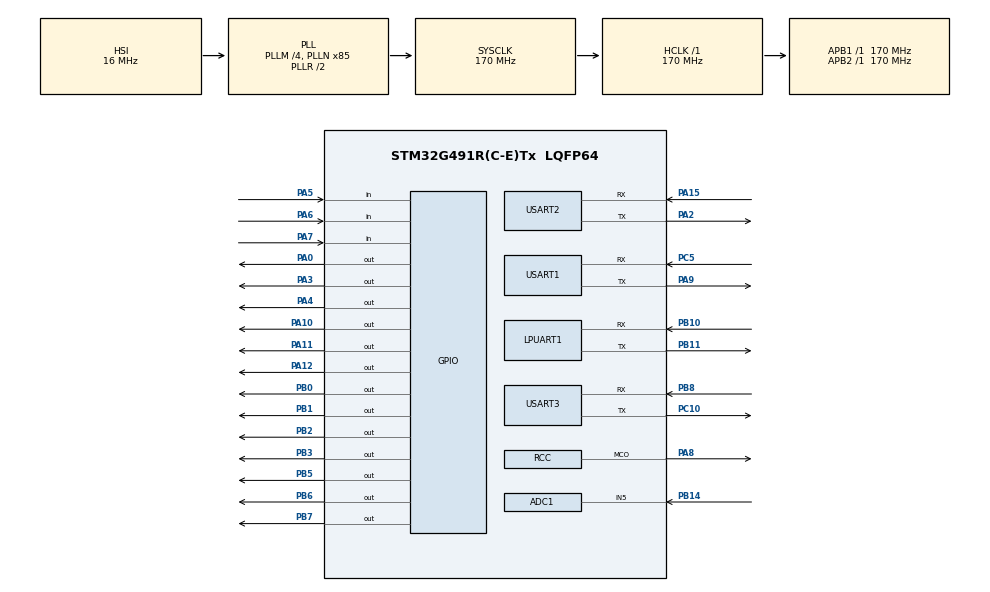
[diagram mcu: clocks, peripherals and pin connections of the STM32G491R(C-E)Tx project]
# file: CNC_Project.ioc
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ADC1.Channel-0\#ChannelRegularConversion=ADC_CHANNEL_5
ADC1.NbrOfConversionFlag=1
ADC1.OffsetNumber-0\#ChannelRegularConversion=ADC_OFFSET_NONE
ADC1.Rank-0\#ChannelRegularConversion=1
ADC1.SamplingTime-0\#ChannelRegularConversion=ADC_SAMPLETIME_2CYCLES_5
ADC1.master=1
Mcu.Family=STM32G4
Mcu.Name=STM32G491R(C-E)Tx
Mcu.Package=LQFP64
NVIC.LPUART1_IRQn=true\:5\:0\:true\:false\:true\:true\:true\:true
NVIC.PriorityGroup=NVIC_PRIORITYGROUP_4
NVIC.RCC_IRQn=true\:0\:0\:false\:false\:true\:true\:false\:true
PA0.Signal=GPIO_Output
PA10.Signal=GPIO_Output
PA11.Signal=GPIO_Output
PA12.Signal=GPIO_Output
PA13.Mode=Serial_Wire
PA13.Signal=SYS_JTMS-SWDIO
PA14.Mode=Serial_Wire
PA14.Signal=SYS_JTCK-SWCLK
PA15.Mode=Asynchronous
PA15.Signal=USART2_RX
PA2.Mode=Asynchronous
PA2.Signal=USART2_TX
PA3.Signal=GPIO_Output
PA4.Signal=GPIO_Output
PA5.Signal=GPIO_Input
PA6.Signal=GPIO_Input
PA7.Signal=GPIO_Input
PA8.Mode=Clock-out
PA8.Signal=RCC_MCO
PA9.Mode=Asynchronous
PA9.Signal=USART1_TX
PB0.Signal=GPIO_Output
PB1.Signal=GPIO_Output
PB10.Mode=Asynchronous
PB10.Signal=LPUART1_RX
PB11.Mode=Asynchronous
PB11.Signal=LPUART1_TX
PB12.Signal=TIM1_BKIN
PB14.Signal=SharedAnalog_PB14
PB2.Signal=GPIO_Output
PB3.Signal=GPIO_Output
PB4.Signal=S_TIM3_CH1
PB5.Signal=GPIO_Output
PB6.Signal=GPIO_Output
PB7.Signal=GPIO_Output
PB8-BOOT0.Mode=Asynchronous
PB8-BOOT0.Signal=USART3_RX
PC0.Signal=S_TIM1_CH1
PC1.Signal=S_TIM1_CH2
PC10.Mode=Asynchronous
PC10.Signal=USART3_TX
PC2.Signal=S_TIM20_CH2
PC5.Mode=Asynchronous
PC5.Signal=USART1_RX
ProjectManager.HeapSize=0x200
ProjectManager.StackSize=0x400
ProjectManager.TargetToolchain=STM32CubeIDE
RCC.ADC12Freq_Value=170000000
RCC.ADC345Freq_Value=170000000
RCC.AHBFreq_Value=170000000
RCC.APB1Freq_Value=170000000
RCC.APB1TimFreq_Value=170000000
RCC.APB2Freq_Value=170000000
RCC.APB2TimFreq_Value=170000000
RCC.CortexFreq_Value=170000000
RCC.EXTERNAL_CLOCK_VALUE=12288000
RCC.HCLKFreq_Value=170000000
RCC.HSE_VALUE=8000000
RCC.HSI48_VALUE=48000000
RCC.HSI_VALUE=16000000
RCC.LSE_VALUE=32768
RCC.PLLM=RCC_PLLM_DIV4
RCC.PLLN=85
RCC.SYSCLKFreq_VALUE=170000000
RCC.SYSCLKSource=RCC_SYSCLKSOURCE_PLLCLK
RCC.VCOOutputFreq_Value=340000000
SH.S_TIM1_CH1.0=TIM1_CH1
SH.S_TIM1_CH2.0=TIM1_CH2
SH.S_TIM20_CH2.0=TIM20_CH2
SH.S_TIM3_CH1.0=TIM3_CH1
SH.SharedAnalog_PB14.0=GPIO_Analog
SH.SharedAnalog_PB14.1=ADC1_IN5,IN5-Single-Ended
USART1.VirtualMode-Asynchronous=VM_ASYNC
USART2.VirtualMode-Asynchronous=VM_ASYNC
USART3.VirtualMode-Asynchronous=VM_ASYNC
VP_SYS_VS_DBSignals.Mode=DisableDeadBatterySignals
VP_TIM1_VS_ClockSourceINT.Mode=Internal
VP_TIM2_VS_ClockSourceITR.Mode=TriggerSource_ITR0
VP_TIM3_VS_ClockSourceINT.Mode=Internal
board=custom

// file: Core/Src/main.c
/* USER CODE BEGIN Header */
/**
  ******************************************************************************
  * @file           : main.c
  * @brief          : Main program body
  ******************************************************************************
  * @attention
  *
  * Copyright (c) 2025 STMicroelectronics.
  * All rights reserved.
  *
  * This software is licensed under terms that can be found in the LICENSE file
  * in the root directory of this software component.
  * If no LICENSE file comes with this software, it is provided AS-IS.
  *
  ******************************************************************************
  */
/* USER CODE END Header */
#include "main.h"

ADC_HandleTypeDef hadc1;

UART_HandleTypeDef hlpuart1;
UART_HandleTypeDef huart1;
UART_HandleTypeDef huart2;
UART_HandleTypeDef huart3;

TIM_HandleTypeDef htim1;
TIM_HandleTypeDef htim2;
TIM_HandleTypeDef htim3;

void SystemClock_Config(void);
static void MX_GPIO_Init(void);
static void MX_TIM2_Init(void);
static void MX_USART3_UART_Init(void);
static void MX_ADC1_Init(void);
static void MX_LPUART1_UART_Init(void);
static void MX_USART1_UART_Init(void);
static void MX_USART2_UART_Init(void);
static void MX_TIM1_Init(void);
static void MX_TIM3_Init(void);

int main(void)
{

  /* MCU Configuration--------------------------------------------------------*/

  /* Reset of all peripherals, Initializes the Flash interface and the Systick. */
  HAL_Init();

  /* Configure the system clock */
  SystemClock_Config();

  /* Initialize all configured peripherals */
  MX_GPIO_Init();
  MX_TIM2_Init();
  MX_USART3_UART_Init();
  MX_ADC1_Init();
  MX_LPUART1_UART_Init();
  MX_USART1_UART_Init();
  MX_USART2_UART_Init();
  MX_TIM1_Init();
  MX_TIM3_Init();
  /* USER CODE BEGIN 2 */
  grbl_enter();
  /* USER CODE END 2 */

  /* Infinite loop */
  while (1)
  {

  }
}

void SystemClock_Config(void)
{
  RCC_OscInitTypeDef RCC_OscInitStruct = {0};
  RCC_ClkInitTypeDef RCC_ClkInitStruct = {0};

  /** Configure the main internal regulator output voltage
  */
  HAL_PWREx_ControlVoltageScaling(PWR_REGULATOR_VOLTAGE_SCALE1_BOOST);

  /** Initializes the RCC Oscillators according to the specified parameters
  * in the RCC_OscInitTypeDef structure.
  */
  RCC_OscInitStruct.OscillatorType = RCC_OSCILLATORTYPE_HSI;
  RCC_OscInitStruct.HSIState = RCC_HSI_ON;
  RCC_OscInitStruct.HSICalibrationValue = RCC_HSICALIBRATION_DEFAULT;
  RCC_OscInitStruct.PLL.PLLState = RCC_PLL_ON;
  RCC_OscInitStruct.PLL.PLLSource = RCC_PLLSOURCE_HSI;
  RCC_OscInitStruct.PLL.PLLM = RCC_PLLM_DIV4;
  RCC_OscInitStruct.PLL.PLLN = 85;
  RCC_OscInitStruct.PLL.PLLP = RCC_PLLP_DIV2;
  RCC_OscInitStruct.PLL.PLLQ = RCC_PLLQ_DIV2;
  RCC_OscInitStruct.PLL.PLLR = RCC_PLLR_DIV2;
  if (HAL_RCC_OscConfig(&RCC_OscInitStruct) != HAL_OK)
  {
    Error_Handler();
  }

  /** Initializes the CPU, AHB and APB buses clocks
  */
  RCC_ClkInitStruct.ClockType = RCC_CLOCKTYPE_HCLK|RCC_CLOCKTYPE_SYSCLK
                              |RCC_CLOCKTYPE_PCLK1|RCC_CLOCKTYPE_PCLK2;
  RCC_ClkInitStruct.SYSCLKSource = RCC_SYSCLKSOURCE_PLLCLK;
  RCC_ClkInitStruct.AHBCLKDivider = RCC_SYSCLK_DIV1;
  RCC_ClkInitStruct.APB1CLKDivider = RCC_HCLK_DIV1;
  RCC_ClkInitStruct.APB2CLKDivider = RCC_HCLK_DIV1;

  if (HAL_RCC_ClockConfig(&RCC_ClkInitStruct, FLASH_LATENCY_4) != HAL_OK)
  {
    Error_Handler();
  }
  HAL_RCC_MCOConfig(RCC_MCO1, RCC_MCO1SOURCE_HSI, RCC_MCODIV_1);
}

static void MX_ADC1_Init(void)
{

  ADC_MultiModeTypeDef multimode = {0};
  ADC_ChannelConfTypeDef sConfig = {0};

  /** Common config
  */
  hadc1.Instance = ADC1;
  hadc1.Init.ClockPrescaler = ADC_CLOCK_SYNC_PCLK_DIV4;
  hadc1.Init.Resolution = ADC_RESOLUTION_12B;
  hadc1.Init.DataAlign = ADC_DATAALIGN_RIGHT;
  hadc1.Init.GainCompensation = 0;
  hadc1.Init.ScanConvMode = ADC_SCAN_DISABLE;
  hadc1.Init.EOCSelection = ADC_EOC_SINGLE_CONV;
  hadc1.Init.LowPowerAutoWait = DISABLE;
  hadc1.Init.ContinuousConvMode = DISABLE;
  hadc1.Init.NbrOfConversion = 1;
  hadc1.Init.DiscontinuousConvMode = DISABLE;
  hadc1.Init.ExternalTrigConv = ADC_SOFTWARE_START;
  hadc1.Init.ExternalTrigConvEdge = ADC_EXTERNALTRIGCONVEDGE_NONE;
  hadc1.Init.DMAContinuousRequests = DISABLE;
  hadc1.Init.Overrun = ADC_OVR_DATA_PRESERVED;
  hadc1.Init.OversamplingMode = DISABLE;
  if (HAL_ADC_Init(&hadc1) != HAL_OK)
  {
    Error_Handler();
  }

  /** Configure the ADC multi-mode
  */
  multimode.Mode = ADC_MODE_INDEPENDENT;
  if (HAL_ADCEx_MultiModeConfigChannel(&hadc1, &multimode) != HAL_OK)
  {
    Error_Handler();
  }

  /** Configure Regular Channel
  */
  sConfig.Channel = ADC_CHANNEL_5;
  sConfig.Rank = ADC_REGULAR_RANK_1;
  sConfig.SamplingTime = ADC_SAMPLETIME_2CYCLES_5;
  sConfig.SingleDiff = ADC_SINGLE_ENDED;
  sConfig.OffsetNumber = ADC_OFFSET_NONE;
  sConfig.Offset = 0;
  if (HAL_ADC_ConfigChannel(&hadc1, &sConfig) != HAL_OK)
  {
    Error_Handler();
  }

}

static void MX_LPUART1_UART_Init(void)
{

  hlpuart1.Instance = LPUART1;
  hlpuart1.Init.BaudRate = 209700;
  hlpuart1.Init.WordLength = UART_WORDLENGTH_8B;
  hlpuart1.Init.StopBits = UART_STOPBITS_1;
  hlpuart1.Init.Parity = UART_PARITY_NONE;
  hlpuart1.Init.Mode = UART_MODE_TX_RX;
  hlpuart1.Init.HwFlowCtl = UART_HWCONTROL_NONE;
  hlpuart1.Init.OneBitSampling = UART_ONE_BIT_SAMPLE_DISABLE;
  hlpuart1.Init.ClockPrescaler = UART_PRESCALER_DIV1;
  hlpuart1.AdvancedInit.AdvFeatureInit = UART_ADVFEATURE_NO_INIT;
  if (HAL_UART_Init(&hlpuart1) != HAL_OK)
  {
    Error_Handler();
  }
  if (HAL_UARTEx_SetTxFifoThreshold(&hlpuart1, UART_TXFIFO_THRESHOLD_1_8) != HAL_OK)
  {
    Error_Handler();
  }
  if (HAL_UARTEx_SetRxFifoThreshold(&hlpuart1, UART_RXFIFO_THRESHOLD_1_8) != HAL_OK)
  {
    Error_Handler();
  }
  if (HAL_UARTEx_DisableFifoMode(&hlpuart1) != HAL_OK)
  {
    Error_Handler();
  }

}

static void MX_USART1_UART_Init(void)
{

  huart1.Instance = USART1;
  huart1.Init.BaudRate = 115200;
  huart1.Init.WordLength = UART_WORDLENGTH_8B;
  huart1.Init.StopBits = UART_STOPBITS_1;
  huart1.Init.Parity = UART_PARITY_NONE;
  huart1.Init.Mode = UART_MODE_TX_RX;
  huart1.Init.HwFlowCtl = UART_HWCONTROL_NONE;
  huart1.Init.OverSampling = UART_OVERSAMPLING_16;
  huart1.Init.OneBitSampling = UART_ONE_BIT_SAMPLE_DISABLE;
  huart1.Init.ClockPrescaler = UART_PRESCALER_DIV1;
  huart1.AdvancedInit.AdvFeatureInit = UART_ADVFEATURE_NO_INIT;
  if (HAL_UART_Init(&huart1) != HAL_OK)
  {
    Error_Handler();
  }
  if (HAL_UARTEx_SetTxFifoThreshold(&huart1, UART_TXFIFO_THRESHOLD_1_8) != HAL_OK)
  {
    Error_Handler();
  }
  if (HAL_UARTEx_SetRxFifoThreshold(&huart1, UART_RXFIFO_THRESHOLD_1_8) != HAL_OK)
  {
    Error_Handler();
  }
  if (HAL_UARTEx_DisableFifoMode(&huart1) != HAL_OK)
  {
    Error_Handler();
  }

}

static void MX_USART2_UART_Init(void)
{

  huart2.Instance = USART2;
  huart2.Init.BaudRate = 115200;
  huart2.Init.WordLength = UART_WORDLENGTH_8B;
  huart2.Init.StopBits = UART_STOPBITS_1;
  huart2.Init.Parity = UART_PARITY_NONE;
  huart2.Init.Mode = UART_MODE_TX_RX;
  huart2.Init.HwFlowCtl = UART_HWCONTROL_NONE;
  huart2.Init.OverSampling = UART_OVERSAMPLING_16;
  huart2.Init.OneBitSampling = UART_ONE_BIT_SAMPLE_DISABLE;
  huart2.Init.ClockPrescaler = UART_PRESCALER_DIV1;
  huart2.AdvancedInit.AdvFeatureInit = UART_ADVFEATURE_NO_INIT;
  if (HAL_UART_Init(&huart2) != HAL_OK)
  {
    Error_Handler();
  }
  if (HAL_UARTEx_SetTxFifoThreshold(&huart2, UART_TXFIFO_THRESHOLD_1_8) != HAL_OK)
  {
    Error_Handler();
  }
  if (HAL_UARTEx_SetRxFifoThreshold(&huart2, UART_RXFIFO_THRESHOLD_1_8) != HAL_OK)
  {
    Error_Handler();
  }
  if (HAL_UARTEx_DisableFifoMode(&huart2) != HAL_OK)
  {
    Error_Handler();
  }

}

static void MX_USART3_UART_Init(void)
{

  huart3.Instance = USART3;
  huart3.Init.BaudRate = 115200;
  huart3.Init.WordLength = UART_WORDLENGTH_8B;
  huart3.Init.StopBits = UART_STOPBITS_1;
  huart3.Init.Parity = UART_PARITY_NONE;
  huart3.Init.Mode = UART_MODE_TX_RX;
  huart3.Init.HwFlowCtl = UART_HWCONTROL_NONE;
  huart3.Init.OverSampling = UART_OVERSAMPLING_16;
  huart3.Init.OneBitSampling = UART_ONE_BIT_SAMPLE_DISABLE;
  huart3.Init.ClockPrescaler = UART_PRESCALER_DIV1;
  huart3.AdvancedInit.AdvFeatureInit = UART_ADVFEATURE_NO_INIT;
  if (HAL_UART_Init(&huart3) != HAL_OK)
  {
    Error_Handler();
  }
  if (HAL_UARTEx_SetTxFifoThreshold(&huart3, UART_TXFIFO_THRESHOLD_1_8) != HAL_OK)
  {
    Error_Handler();
  }
  if (HAL_UARTEx_SetRxFifoThreshold(&huart3, UART_RXFIFO_THRESHOLD_1_8) != HAL_OK)
  {
    Error_Handler();
  }
  if (HAL_UARTEx_DisableFifoMode(&huart3) != HAL_OK)
  {
    Error_Handler();
  }

}

static void MX_TIM1_Init(void)
{

  TIM_ClockConfigTypeDef sClockSourceConfig = {0};
  TIM_MasterConfigTypeDef sMasterConfig = {0};

  htim1.Instance = TIM1;
  htim1.Init.Prescaler = 0;
  htim1.Init.CounterMode = TIM_COUNTERMODE_UP;
  htim1.Init.Period = 65535;
  htim1.Init.ClockDivision = TIM_CLOCKDIVISION_DIV1;
  htim1.Init.RepetitionCounter = 0;
  htim1.Init.AutoReloadPreload = TIM_AUTORELOAD_PRELOAD_DISABLE;
  if (HAL_TIM_Base_Init(&htim1) != HAL_OK)
  {
    Error_Handler();
  }
  sClockSourceConfig.ClockSource = TIM_CLOCKSOURCE_INTERNAL;
  if (HAL_TIM_ConfigClockSource(&htim1, &sClockSourceConfig) != HAL_OK)
  {
    Error_Handler();
  }
  sMasterConfig.MasterOutputTrigger = TIM_TRGO_RESET;
  sMasterConfig.MasterOutputTrigger2 = TIM_TRGO2_RESET;
  sMasterConfig.MasterSlaveMode = TIM_MASTERSLAVEMODE_DISABLE;
  if (HAL_TIMEx_MasterConfigSynchronization(&htim1, &sMasterConfig) != HAL_OK)
  {
    Error_Handler();
  }

}

static void MX_TIM2_Init(void)
{

  TIM_SlaveConfigTypeDef sSlaveConfig = {0};
  TIM_MasterConfigTypeDef sMasterConfig = {0};

  htim2.Instance = TIM2;
  htim2.Init.Prescaler = 0;
  htim2.Init.CounterMode = TIM_COUNTERMODE_UP;
  htim2.Init.Period = 4294967295;
  htim2.Init.ClockDivision = TIM_CLOCKDIVISION_DIV1;
  htim2.Init.AutoReloadPreload = TIM_AUTORELOAD_PRELOAD_DISABLE;
  if (HAL_TIM_Base_Init(&htim2) != HAL_OK)
  {
    Error_Handler();
  }
  sSlaveConfig.SlaveMode = TIM_SLAVEMODE_DISABLE;
  sSlaveConfig.InputTrigger = TIM_TS_ITR0;
  if (HAL_TIM_SlaveConfigSynchro(&htim2, &sSlaveConfig) != HAL_OK)
  {
    Error_Handler();
  }
  sMasterConfig.MasterOutputTrigger = TIM_TRGO_RESET;
  sMasterConfig.MasterSlaveMode = TIM_MASTERSLAVEMODE_DISABLE;
  if (HAL_TIMEx_MasterConfigSynchronization(&htim2, &sMasterConfig) != HAL_OK)
  {
    Error_Handler();
  }

}

static void MX_TIM3_Init(void)
{

  TIM_ClockConfigTypeDef sClockSourceConfig = {0};
  TIM_MasterConfigTypeDef sMasterConfig = {0};

  htim3.Instance = TIM3;
  htim3.Init.Prescaler = 0;
  htim3.Init.CounterMode = TIM_COUNTERMODE_UP;
  htim3.Init.Period = 65535;
  htim3.Init.ClockDivision = TIM_CLOCKDIVISION_DIV1;
  htim3.Init.AutoReloadPreload = TIM_AUTORELOAD_PRELOAD_DISABLE;
  if (HAL_TIM_Base_Init(&htim3) != HAL_OK)
  {
    Error_Handler();
  }
  sClockSourceConfig.ClockSource = TIM_CLOCKSOURCE_INTERNAL;
  if (HAL_TIM_ConfigClockSource(&htim3, &sClockSourceConfig) != HAL_OK)
  {
    Error_Handler();
  }
  sMasterConfig.MasterOutputTrigger = TIM_TRGO_RESET;
  sMasterConfig.MasterSlaveMode = TIM_MASTERSLAVEMODE_DISABLE;
  if (HAL_TIMEx_MasterConfigSynchronization(&htim3, &sMasterConfig) != HAL_OK)
  {
    Error_Handler();
  }

}

static void MX_GPIO_Init(void)
{
  GPIO_InitTypeDef GPIO_InitStruct = {0};

  /* GPIO Ports Clock Enable */
  __HAL_RCC_GPIOC_CLK_ENABLE();
  __HAL_RCC_GPIOA_CLK_ENABLE();
  __HAL_RCC_GPIOB_CLK_ENABLE();

  /*Configure GPIO pin Output Level */
  HAL_GPIO_WritePin(GPIOA, GPIO_PIN_0|GPIO_PIN_3|GPIO_PIN_4|GPIO_PIN_10
                          |GPIO_PIN_11|GPIO_PIN_12, GPIO_PIN_RESET);

  /*Configure GPIO pin Output Level */
  HAL_GPIO_WritePin(GPIOB, GPIO_PIN_0|GPIO_PIN_1|GPIO_PIN_2|GPIO_PIN_3
                          |GPIO_PIN_5|GPIO_PIN_6|GPIO_PIN_7, GPIO_PIN_RESET);

  /*Configure GPIO pin : PC2 */
  GPIO_InitStruct.Pin = GPIO_PIN_2;
  GPIO_InitStruct.Mode = GPIO_MODE_AF_PP;
  GPIO_InitStruct.Pull = GPIO_NOPULL;
  GPIO_InitStruct.Speed = GPIO_SPEED_FREQ_LOW;
  GPIO_InitStruct.Alternate = GPIO_AF6_TIM20;
  HAL_GPIO_Init(GPIOC, &GPIO_InitStruct);

  /*Configure GPIO pins : PA0 PA3 PA4 PA10
                           PA11 PA12 */
  GPIO_InitStruct.Pin = GPIO_PIN_0|GPIO_PIN_3|GPIO_PIN_4|GPIO_PIN_10
                          |GPIO_PIN_11|GPIO_PIN_12;
  GPIO_InitStruct.Mode = GPIO_MODE_OUTPUT_PP;
  GPIO_InitStruct.Pull = GPIO_NOPULL;
  GPIO_InitStruct.Speed = GPIO_SPEED_FREQ_LOW;
  HAL_GPIO_Init(GPIOA, &GPIO_InitStruct);

  /*Configure GPIO pins : PA5 PA6 PA7 */
  GPIO_InitStruct.Pin = GPIO_PIN_5|GPIO_PIN_6|GPIO_PIN_7;
  GPIO_InitStruct.Mode = GPIO_MODE_INPUT;
  GPIO_InitStruct.Pull = GPIO_NOPULL;
  HAL_GPIO_Init(GPIOA, &GPIO_InitStruct);

  /*Configure GPIO pins : PB0 PB1 PB2 PB3
                           PB5 PB6 PB7 */
  GPIO_InitStruct.Pin = GPIO_PIN_0|GPIO_PIN_1|GPIO_PIN_2|GPIO_PIN_3
                          |GPIO_PIN_5|GPIO_PIN_6|GPIO_PIN_7;
  GPIO_InitStruct.Mode = GPIO_MODE_OUTPUT_PP;
  GPIO_InitStruct.Pull = GPIO_NOPULL;
  GPIO_InitStruct.Speed = GPIO_SPEED_FREQ_LOW;
  HAL_GPIO_Init(GPIOB, &GPIO_InitStruct);

  /*Configure GPIO pin : PA8 */
  GPIO_InitStruct.Pin = GPIO_PIN_8;
  GPIO_InitStruct.Mode = GPIO_MODE_AF_PP;
  GPIO_InitStruct.Pull = GPIO_NOPULL;
  GPIO_InitStruct.Speed = GPIO_SPEED_FREQ_LOW;
  GPIO_InitStruct.Alternate = GPIO_AF0_MCO;
  HAL_GPIO_Init(GPIOA, &GPIO_InitStruct);

}

void Error_Handler(void)
{
  __disable_irq();
  while (1)
  {
  }
}
